# STM32L151xD register map
File version: 1.0
Registers are 32-bit, read-write, reset 0x0 unless marked. A register's access mark holds for its fields unless they carry their own. Offsets are from the block's base; [hi:lo] are bit positions; {n}, {i} and the like mark numbered series.

## OPAMP123_COMMON
Base 0x40007C5C; alternate view of OPAMP
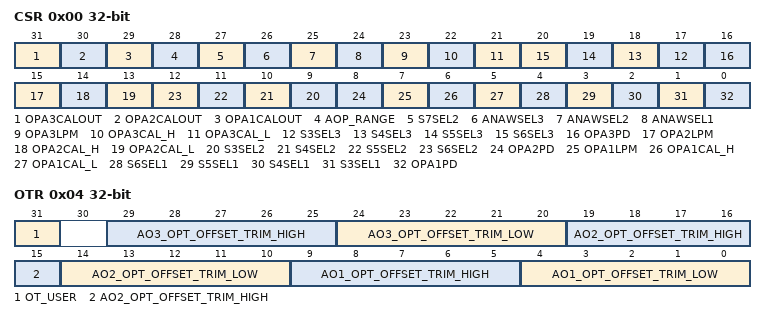
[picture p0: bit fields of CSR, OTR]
0x00 CSR — OPAMP control and status register, used for bits common to several OPAMP instances
  [31] OPA3CALOUT — OPAMP3 calibration output
  [30] OPA2CALOUT — OPAMP2 calibration output
  [29] OPA1CALOUT — OPAMP1 calibration output
  [28] AOP_RANGE — Common to several OPAMP instances: Operational amplifier voltage supply range. Bit intended to be used with OPAMP common instance (OPAMP_Common_TypeDef)
    0=LOW (Power supply range low. On STM32L1 series: Vdda lower than 2.4V.); 1=HIGH (Power supply range high. On STM32L1 series: Vdda higher than 2.4V.)
  [27] S7SEL2 — Switch 7 for OPAMP2 Enable
  [26] ANAWSEL3 — Switch ANA Enable for OPAMP3
  [25] ANAWSEL2 — Switch ANA Enable for OPAMP2
  [24] ANAWSEL1 — Switch ANA Enable for OPAMP1
  [23] OPA3LPM — OPAMP3 Low power enable
  [22] OPA3CAL_H — OPAMP3 Offset calibration for N differential pair
  [21] OPA3CAL_L — OPAMP3 Offset calibration for P differential pair
  [n+14] S{n}SEL3 (n=3..6) — Switch {n} for OPAMP3 Enable
  [16] OPA3PD — OPAMP3 disable
  [15] OPA2LPM — OPAMP2 Low power enable
  [14] OPA2CAL_H — OPAMP2 Offset calibration for N differential pair
  [13] OPA2CAL_L — OPAMP2 Offset calibration for P differential pair
  [n+6] S{n}SEL2 (n=3..6) — Switch {n} for OPAMP2 Enable
  [8] OPA2PD — OPAMP2 disable
  [7] OPA1LPM — OPAMP1 Low power enable
  [6] OPA1CAL_H — OPAMP1 Offset calibration for N differential pair
  [5] OPA1CAL_L — OPAMP1 Offset calibration for P differential pair
  [4] S6SEL1 — Switch 6 for OPAMP1 Enable
  [3] S5SEL1 — Switch 5 for OPAMP1 Enable
  [2] S4SEL1 — Switch 4 for OPAMP1 Enable
  [1] S3SEL1 — Switch 3 for OPAMP1 Enable
    0=STANDALONE (OPAMP functional mode, OPAMP operation in standalone (on STM32L1 series, it corresponds to OPAMP internal switches S3 opened (switch SanB state depends on switch S4 state))); 1=FOLLOWER (OPAMP functional mode, OPAMP operation in follower (on STM32L1 series, it corresponds to OPAMP internal switches S3 and SanB closed))
  [0] OPA1PD — OPAMP1 disable
0x04 OTR — OPAMP
  [31] OT_USER — Switch to OPAMP offset user trimmed values
    0=FACTORY (OPAMP trimming factors set to factory values); 1=USER (OPAMP trimming factors set to user values)
  [29:25] AO3_OPT_OFFSET_TRIM_HIGH — Offset trim for transistors differential pair NMOS of OPAMP3
  [24:20] AO3_OPT_OFFSET_TRIM_LOW — Offset trim for transistors differential pair PMOS of OPAMP3
  [19:15] AO2_OPT_OFFSET_TRIM_HIGH — Offset trim for transistors differential pair NMOS of OPAMP2
  [14:10] AO2_OPT_OFFSET_TRIM_LOW — Offset trim for transistors differential pair PMOS of OPAMP2
  [9:5] AO1_OPT_OFFSET_TRIM_HIGH — Offset trim for transistors differential pair NMOS of OPAMP1
  [4:0] AO1_OPT_OFFSET_TRIM_LOW — Offset trim for transistors differential pair PMOS of OPAMP1

## SYSCFG — SysTem Configuration
Base 0x40010000
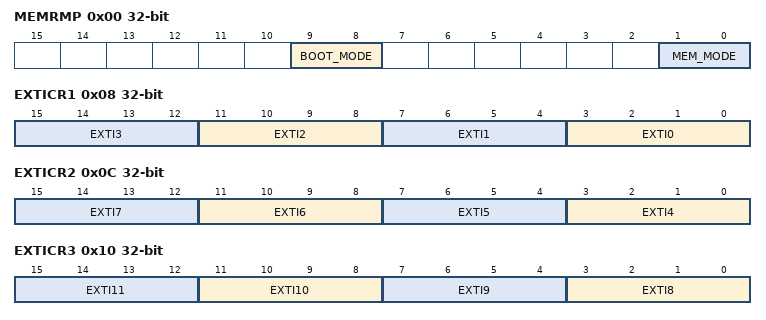
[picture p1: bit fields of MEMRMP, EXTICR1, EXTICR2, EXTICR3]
0x00 MEMRMP — SYSCFG memory remap register
  [9:8] BOOT_MODE — Boot mode Config
    0=FLASH; 1=SYSTEMFLASH; 2=FSMC; 3=SRAM
  [1:0] MEM_MODE — SYSCFG_Memory Remap Config
    0=FLASH; 1=SYSTEMFLASH; 3=SRAM; 2=FMC
0x04 PMC — SYSCFG peripheral mode configuration register
  [0] USB_PU — SYSCFG PMC
0x08 EXTICR1 — SYSCFG external interrupt configuration registers
  [4n+3:4n] EXTI{n} (n=0..3) — EXTI {n} configuration
0x0C EXTICR2 — SYSCFG external interrupt configuration registers
  [4n-13:4n-16] EXTI{n} (n=4..7) — EXTI {n} configuration
0x10 EXTICR3 — SYSCFG external interrupt configuration registers
  [4n-29:4n-32] EXTI{n} (n=8..11) — EXTI {n} configuration
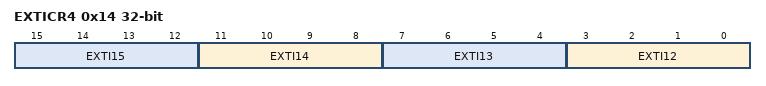
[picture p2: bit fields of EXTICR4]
0x14 EXTICR4 — SYSCFG external interrupt configuration registers
  [4n-45:4n-48] EXTI{n} (n=12..15) — EXTI {n} configuration

## EXTI — External Interrupt/Event Controller
Base 0x40010400
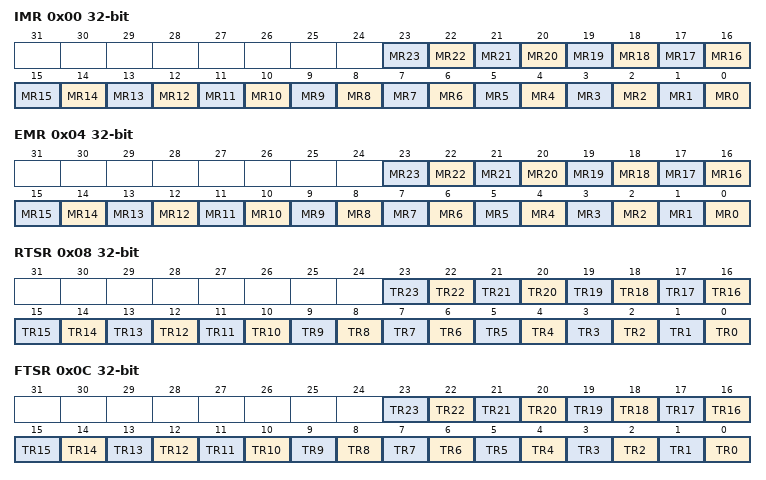
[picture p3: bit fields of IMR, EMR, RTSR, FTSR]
0x00 IMR — EXTI Interrupt mask register
  [n] MR{n} (n=0..23) — Interrupt Mask on line {n}
0x04 EMR — EXTI Event mask register
  [n] MR{n} (n=0..23) — Event Mask on line {n}
0x08 RTSR — EXTI Rising trigger selection register
  [n] TR{n} (n=0..23) — Rising trigger event configuration bit of line {n}
0x0C FTSR — EXTI Falling trigger selection register
  [n] TR{n} (n=0..23) — Falling trigger event configuration bit of line {n}
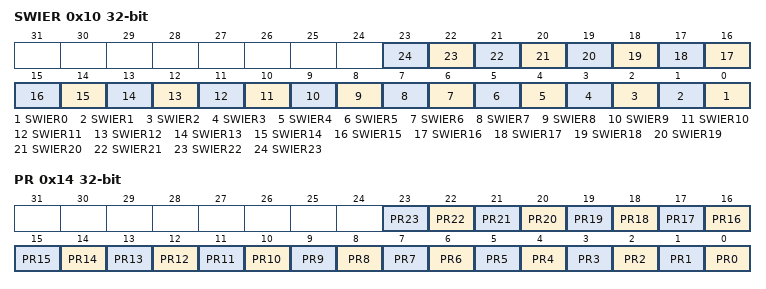
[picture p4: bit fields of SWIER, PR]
0x10 SWIER — EXTI Software interrupt event register
  [n] SWIER{n} (n=0..23) — Software Interrupt on line {n}
0x14 PR — EXTI Pending register
  [n] PR{n} (n=0..23) — Pending bit for line {n}
